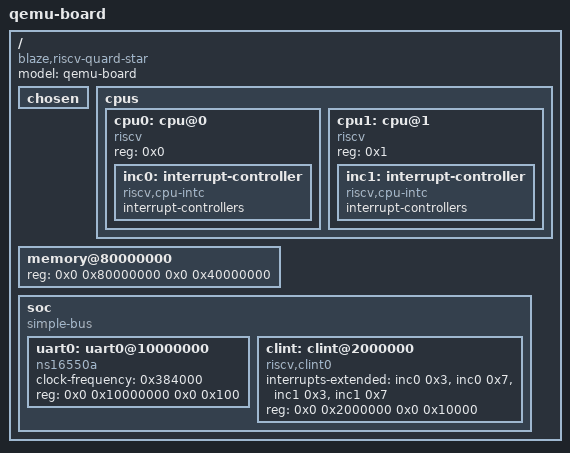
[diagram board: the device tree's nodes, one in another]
/dts-v1/; /* means that the file's content are in version of the DTS syntax */

/ {	/* root */
	/* compatible = "manufacture, model" */
	// compatible = "blaze,qemu-board";
	// model = "" define by yourself
	// reg -->
	#address-cells = <0x2>; 
	#size-cells = <0x2>;
	compatible = "blaze,riscv-quard-star";
	model = "qemu-board";

	/* pass args for linux or u-boot*/
	chosen {
	};

	/* one riscv64-core */
	cpus {
		#address-cells = <1>;
		#size-cells = <0>;
		//timebase-frequency = <10000000>;

		cpu0: cpu@0{
			reg = <0x0>;
			device_type = "cpu";
			compatible = "riscv";

			inc0:interrupt-controller{
				phandle=<0x1>;
				#interrupt-cells=<0x1>;
				interrupt-controllers;
				compatible="riscv,cpu-intc";
			};
		};

		cpu1: cpu@1{
			reg = <0x1>;/* FIXME: what does it mean? */
			device_type = "cpu";
			compatible = "riscv";

			inc1:interrupt-controller{
				phandle=<0x2>;
				#interrupt-cells=<0x1>;
				interrupt-controllers;
				compatible="riscv,cpu-intc";
			};
		};
	};


	memory@80000000 {
		device_type = "memory";
		// addr: 0x80000000
		// size: 0x40000000
		reg = <0x0 0x80000000 0x0 0x40000000>;
	};

	soc {
		#address-cells = <0x2>; 
		#size-cells = <0x2>;
		compatible = "simple-bus";

		uart0: uart0@10000000{
			clock-frequency = <0x384000>;
			reg = <0x0 0x10000000 0x0 0x100>;
			compatible = "ns16550a";
		};

		clint: clint@2000000 {
			// format <phandle> <prop-encoded-array>
			interrupts-extended = <&inc0 0x3>, <&inc0 0x7>, <&inc1 0x3>, <&inc1 0x7>; // 0x03 software interrupt  0x07 timer interrupt
			reg = <0x0 0x2000000 0x0 0x10000>;
			compatible = "riscv,clint0";
		};

	};

};
